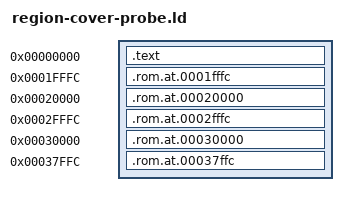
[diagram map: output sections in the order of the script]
/* GENERATED by tb/verilator/ctrl_region_decode/run.py; DO NOT EDIT. */
ENTRY(_start)
SECTIONS
{
	.text 0x00000000 : { KEEP(*(.text.start)) *(.text .text.*) *(.rodata .rodata.*) }
	.rom.at.0001fffc 0x0001fffc : { KEEP(*(.rom.at.0001fffc)) }
	.rom.at.00020000 0x00020000 : { KEEP(*(.rom.at.00020000)) }
	.rom.at.0002fffc 0x0002fffc : { KEEP(*(.rom.at.0002fffc)) }
	.rom.at.00030000 0x00030000 : { KEEP(*(.rom.at.00030000)) }
	.rom.at.00037ffc 0x00037ffc : { KEEP(*(.rom.at.00037ffc)) }
	/DISCARD/ : { *(.comment) *(.note .note.*) }
}
